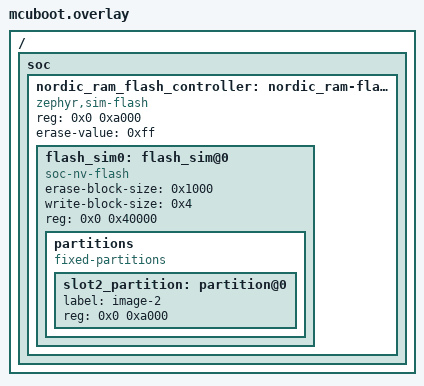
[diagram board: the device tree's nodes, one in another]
/*
 * Copyright (c) 2021 Nordic Semiconductor ASA
 *
 * SPDX-License-Identifier: Apache-2.0
 */

/*
 * This file is used to enable a partition which is used through the flash API
 * but which is in reality stored in RAM. This is done to load data from
 * external flash to the network core. Since the network core cannot access
 * the external flash directly, the data is buffered in RAM before being
 * copied by the network core to the network core flash.
 */

/ {
	soc {
		/* Add a flash controller which has the compatible
		 * 'zephyr,sim-flash'. This will ensure that the flash
		 * simulator can use it. None of the other properties in this
		 * node is used for anything.
		 */
		nordic_ram_flash_controller: nordic_ram-flash-controller@0 {
			compatible = "zephyr,sim-flash";
			reg = < 0x0 0xa000 >;
			#address-cells = < 0x1 >;
			#size-cells = < 0x1 >;
			erase-value = < 0xff >;
			flash_sim0: flash_sim@0 {
				status = "okay";
				compatible = "soc-nv-flash";
				erase-block-size = < 0x1000 >;
				write-block-size = < 0x4 >;
				reg = < 0x0 0x40000 >;
				partitions {
					compatible = "fixed-partitions";
					#address-cells = < 0x1 >;
					#size-cells = < 0x1 >;
					slot2_partition: partition@0 {
						label = "image-2";
						reg = < 0x0 0xa000 >;
					};
				};
			};
		};
	};
};
